# CH583SFR register map
Vendor: WCH Ltd.; Series: CH58x; File version: 1.1
CPU: RISC-V r0p0, little endian, no MPU, no FPU, 2 interrupt priority bits
Registers are 8-bit, read-write, reset 0x0 unless marked. A register's access mark holds for its fields unless they carry their own. Offsets are from the block's base; [hi:lo] are bit positions; {n}, {i} and the like mark numbered series.

## PFIC — Program Fast Interrupt Controller
Base 0xE000E000
0x00 ISR1 32-bit ro — RO,Interrupt Status Register 1
  [31:12] INTENSTA — Interrupt ID Status
0x04 ISR2 32-bit ro — RO,Interrupt Status Register 2
  [3:0] INTENSTA — Interrupt ID Status
0x20 IPR1 32-bit ro — RO,Interrupt Pending Register 1
  [31:12] PENDSTA
0x24 IPR2 32-bit ro — RO,Interrupt Pending Register 2
  [3:0] PENDSTA
0x40 ITHRESDR 32-bit — RW,Interrupt Priority Register
  [7:0] THRESHOLD — RW,THRESHOLD
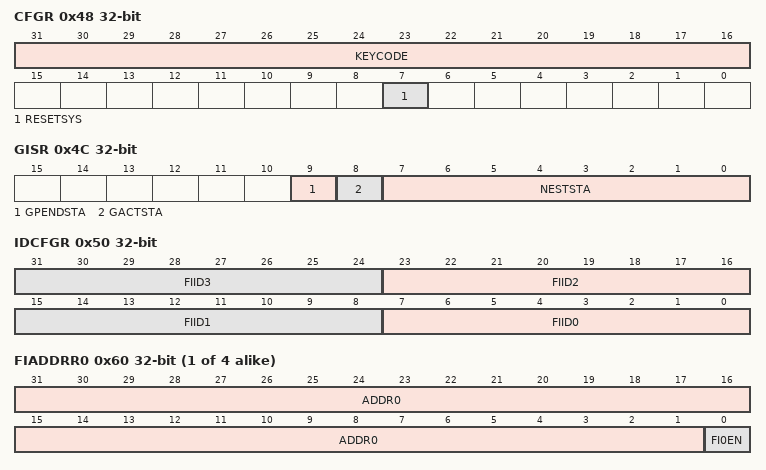
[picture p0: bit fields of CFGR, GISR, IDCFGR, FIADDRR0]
0x48 CFGR 32-bit wo — Interrupt Config Register
  [31:16] KEYCODE — WO,KEYCODE
  [7] RESETSYS — WO,RESETSYS
0x4C GISR 32-bit ro — Interrupt Global Register
  [9] GPENDSTA — RO,GPENDSTA
  [8] GACTSTA — RO,GACTSTA
  [7:0] NESTSTA — RO,NESTSTA
0x50 IDCFGR 32-bit — RW,Interrupt Fast ID Config Register
  [8n+7:8n] FIID{n} (n=0..3) — RW,FIID{n}
{0x60+4i} FIADDRR{i} 32-bit (i=0..3) — Interrupt {i} address Register
  [31:1] ADDR{i} — RW,ADDR{i}
  [0] FI{i}EN — RW,FI{i}EN
0x100 IENR1 32-bit wo — Interrupt Setting Register
  [31:12] INTEN — RW1,INTEN
0x104 IENR2 32-bit wo — Interrupt Setting Register
  [3:0] INTEN — RW1,INTEN
0x180 IRER1 32-bit wo — Interrupt Clear Register
  [31:12] INTRESET — RW1,INTRESET
0x184 IRER2 32-bit wo — Interrupt Clear Register
  [3:0] INTRESET — RW1,INTRESET
0x200 IPSR1 32-bit wo — Interrupt Pending Register
  [31:12] PENDSET — RW1,PENDSET
0x204 IPSR2 32-bit wo — Interrupt Pending Register
  [3:0] PENDSET — RW1,PENDSET
0x280 IPRR1 32-bit wo — Interrupt Pending Clear Register
  [31:12] PENDRESET — RW1,PENDRESET
0x284 IPRR2 32-bit wo — Interrupt Pending Clear Register
  [3:0] PENDRESET — RW1,PENDRESET
0x300 IACTR1 32-bit — Interrupt ACTIVE Register
  [31:12] IACTS — RW1,IACTS
0x304 IACTR2 32-bit — Interrupt ACTIVE Register
  [3:0] IACTS — RW1,IACTS
0x400 IPRIOR0 32-bit — Interrupt Priority configuration Register 0
  [31:0] IPRIOR0 — RW,Interrupt priority for number 0-3
{0x400+0x20*i} IPRIOR{i} 32-bit (i=1..10) — Interrupt Priority configuration Register {i}
  [31:0] IPRIOR{i} — >RW,Interrupt priority for number {4i}-{4i+3}
{0x400+0x20*i} IPRIOR{i} 32-bit (i=11..19) — Interrupt Priority configuration Register {i}
  [31:0] IPRIOR{i} — RW,Interrupt priority for number {4i}-{4i+3}
0x680 IPRIOR20 32-bit — Interrupt Priority configuration Register 20
  [31:0] IPRIOR20 — RW,RW,Interrupt priority for number 80-83
{0x400+0x20*i} IPRIOR{i} 32-bit (i=21..53) — Interrupt Priority configuration Register {i}
  [31:0] IPRIOR{i} — RW,Interrupt priority for number {4i}-{4i+3}
0xAD0 IPRIOR54 32-bit — Interrupt Priority configuration Register 54
  [31:0] IPRIOR54 — RW,Interrupt priority for number 216-219
{0x400+0x20*i} IPRIOR{i} 32-bit (i=55..61) — Interrupt Priority configuration Register {i}
  [31:0] IPRIOR{i} — RW,Interrupt priority for number {4i}-{4i+3}
0xBE0 IPRIOR62 32-bit — Interrupt Priority configuration Register 62
  [31:0] IPRIOR62 — RW,Interrupt priority for number 248-251
0xC00 IPRIOR63 32-bit — Interrupt Priority configuration Register 63
  [31:0] IPRIOR63 — RW,Interrupt priority for number 252-255
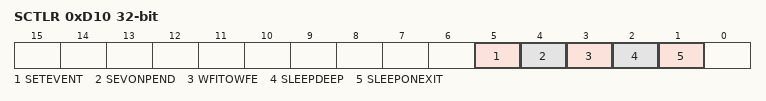
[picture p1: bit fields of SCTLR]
0xD10 SCTLR 32-bit — System Control Register
  [5] SETEVENT — WO,SETEVENT
  [4] SEVONPEND — RW,SEVONPEND
  [3] WFITOWFE — RW,WFITOWFE
  [2] SLEEPDEEP — RW,SLEEPDEEP
  [1] SLEEPONEXIT — RW,SLEEPONEXIT

## Systick
Base 0xE000F000
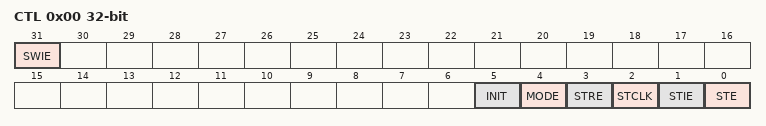
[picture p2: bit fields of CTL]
0x00 CTL 32-bit — Systick counter control register
  [31] SWIE — RW0,System soft interrupt enable
  [5] INIT — Initial counter value updated
  [4] MODE — counter mode
  [3] STRE — System counter reload control
  [2] STCLK — System counter clock Source selection
  [1] STIE — Systick counter interrupt enable
  [0] STE — Systick counter enable
0x04 S 32-bit — Systick count status register
  [0] CNTIF — RW,CNTIF
0x08 CNT 64-bit (reset mask 0xFFFFFFFF) — Systick counter register
  [63:0] CNT — RW,CNT
0x10 CMP 64-bit (reset mask 0xFFFFFFFF) — Systick compare register
  [63:0] CMP — RW,CMP
